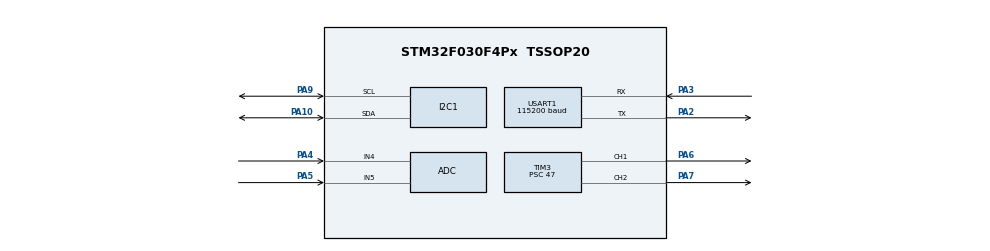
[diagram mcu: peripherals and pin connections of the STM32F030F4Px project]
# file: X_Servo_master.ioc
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ADC.ContinuousConvMode=ENABLE
ADC.EOCSelection=ADC_EOC_SEQ_CONV
ADC.SamplingTime=ADC_SAMPLETIME_7CYCLES_5
I2C1.NoStretchMode=I2C_NOSTRETCH_ENABLE
Mcu.Family=STM32F0
Mcu.Name=STM32F030F4Px
Mcu.Package=TSSOP20
PA10.Mode=I2C
PA10.Signal=I2C1_SDA
PA13.Mode=Serial_Wire
PA13.Signal=SYS_SWDIO
PA14.Mode=Serial_Wire
PA14.Signal=SYS_SWCLK
PA2.Mode=Asynchronous
PA2.Signal=USART1_TX
PA3.Mode=Asynchronous
PA3.Signal=USART1_RX
PA4.Signal=SharedAnalog_PA4
PA5.Signal=SharedAnalog_PA5
PA6.Signal=S_TIM3_CH1
PA7.Signal=S_TIM3_CH2
PA9.Mode=I2C
PA9.Signal=I2C1_SCL
ProjectManager.HeapSize=0x200
ProjectManager.StackSize=0x400
ProjectManager.TargetToolchain=STM32CubeIDE
RCC.AHBFreq_Value=48000000
RCC.APB1Freq_Value=48000000
RCC.APB1TimFreq_Value=48000000
RCC.HCLKFreq_Value=48000000
RCC.PLLMUL=RCC_PLL_MUL12
RCC.SYSCLKFreq_VALUE=48000000
RCC.SYSCLKSource=RCC_SYSCLKSOURCE_PLLCLK
SH.S_TIM3_CH1.0=TIM3_CH1,PWM Generation1 CH1
SH.S_TIM3_CH2.0=TIM3_CH2,PWM Generation2 CH2
SH.SharedAnalog_PA4.0=GPIO_Analog
SH.SharedAnalog_PA4.1=ADC_IN4,IN4
SH.SharedAnalog_PA5.0=GPIO_Analog
SH.SharedAnalog_PA5.1=ADC_IN5,IN5
TIM17.AutoReloadPreload=TIM_AUTORELOAD_PRELOAD_ENABLE
TIM3.AutoReloadPreload=TIM_AUTORELOAD_PRELOAD_ENABLE
TIM3.Channel-PWM\ Generation1\ CH1=TIM_CHANNEL_1
TIM3.Channel-PWM\ Generation2\ CH2=TIM_CHANNEL_2
TIM3.Period=999
TIM3.Prescaler=47
USART1.BaudRate=115200
USART1.VirtualMode-Asynchronous=VM_ASYNC
VP_TIM17_VS_ClockSourceINT.Mode=Enable_Timer
board=custom

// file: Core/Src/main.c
/* USER CODE BEGIN Header */
/**
  ******************************************************************************
  * @file           : main.c
  * @brief          : Main program body
  ******************************************************************************
  * @attention
  *
  * Copyright (c) 2022 STMicroelectronics.
  * All rights reserved.
  *
  * This software is licensed under terms that can be found in the LICENSE file
  * in the root directory of this software component.
  * If no LICENSE file comes with this software, it is provided AS-IS.
  *
  ******************************************************************************
  */
/* USER CODE END Header */
#include "main.h"
#include "adc.h"
#include "i2c.h"
#include "tim.h"
#include "usart.h"
#include "gpio.h"

/* USER CODE BEGIN Includes */
#include "motor.h"
/* USER CODE END Includes */

void SystemClock_Config(void);

int main(void)
{

  /* MCU Configuration--------------------------------------------------------*/

  /* Reset of all peripherals, Initializes the Flash interface and the Systick. */
  HAL_Init();

  /* Configure the system clock */
  SystemClock_Config();

  /* Initialize all configured peripherals */
  MX_GPIO_Init();
  MX_I2C1_Init();
  MX_TIM3_Init();
  MX_USART1_UART_Init();
  MX_TIM17_Init();
  MX_ADC_Init();
  /* USER CODE BEGIN 2 */
  Motor_Init();
  /* USER CODE END 2 */

  /* Infinite loop */
  /* USER CODE BEGIN WHILE */
  while (1)
  {
	  /*MOTOR TEST*/
/*	  Motor_Move(forward, 299);
	  HAL_Delay(1000);
	  Motor_Move(backward, 299);
	  HAL_Delay(1000);
	  Motor_Move(stop, 0);
	  HAL_Delay(1000);*/

    /* USER CODE END WHILE */

  }
}

void SystemClock_Config(void)
{
  LL_FLASH_SetLatency(LL_FLASH_LATENCY_1);
  while(LL_FLASH_GetLatency() != LL_FLASH_LATENCY_1)
  {
  }
  LL_RCC_HSI_Enable();

   /* Wait till HSI is ready */
  while(LL_RCC_HSI_IsReady() != 1)
  {

  }
  LL_RCC_HSI_SetCalibTrimming(16);
  LL_RCC_HSI14_Enable();

   /* Wait till HSI14 is ready */
  while(LL_RCC_HSI14_IsReady() != 1)
  {

  }
  LL_RCC_HSI14_SetCalibTrimming(16);
  LL_RCC_PLL_ConfigDomain_SYS(LL_RCC_PLLSOURCE_HSI_DIV_2, LL_RCC_PLL_MUL_12);
  LL_RCC_PLL_Enable();

   /* Wait till PLL is ready */
  while(LL_RCC_PLL_IsReady() != 1)
  {

  }
  LL_RCC_SetAHBPrescaler(LL_RCC_SYSCLK_DIV_1);
  LL_RCC_SetAPB1Prescaler(LL_RCC_APB1_DIV_1);
  LL_RCC_SetSysClkSource(LL_RCC_SYS_CLKSOURCE_PLL);

   /* Wait till System clock is ready */
  while(LL_RCC_GetSysClkSource() != LL_RCC_SYS_CLKSOURCE_STATUS_PLL)
  {

  }
  LL_SetSystemCoreClock(48000000);

   /* Update the time base */
  if (HAL_InitTick (TICK_INT_PRIORITY) != HAL_OK)
  {
    Error_Handler();
  }
  LL_RCC_HSI14_EnableADCControl();
  LL_RCC_SetUSARTClockSource(LL_RCC_USART1_CLKSOURCE_PCLK1);
  LL_RCC_SetI2CClockSource(LL_RCC_I2C1_CLKSOURCE_HSI);
}

void Error_Handler(void)
{
  __disable_irq();
  while (1)
  {
  }
}
